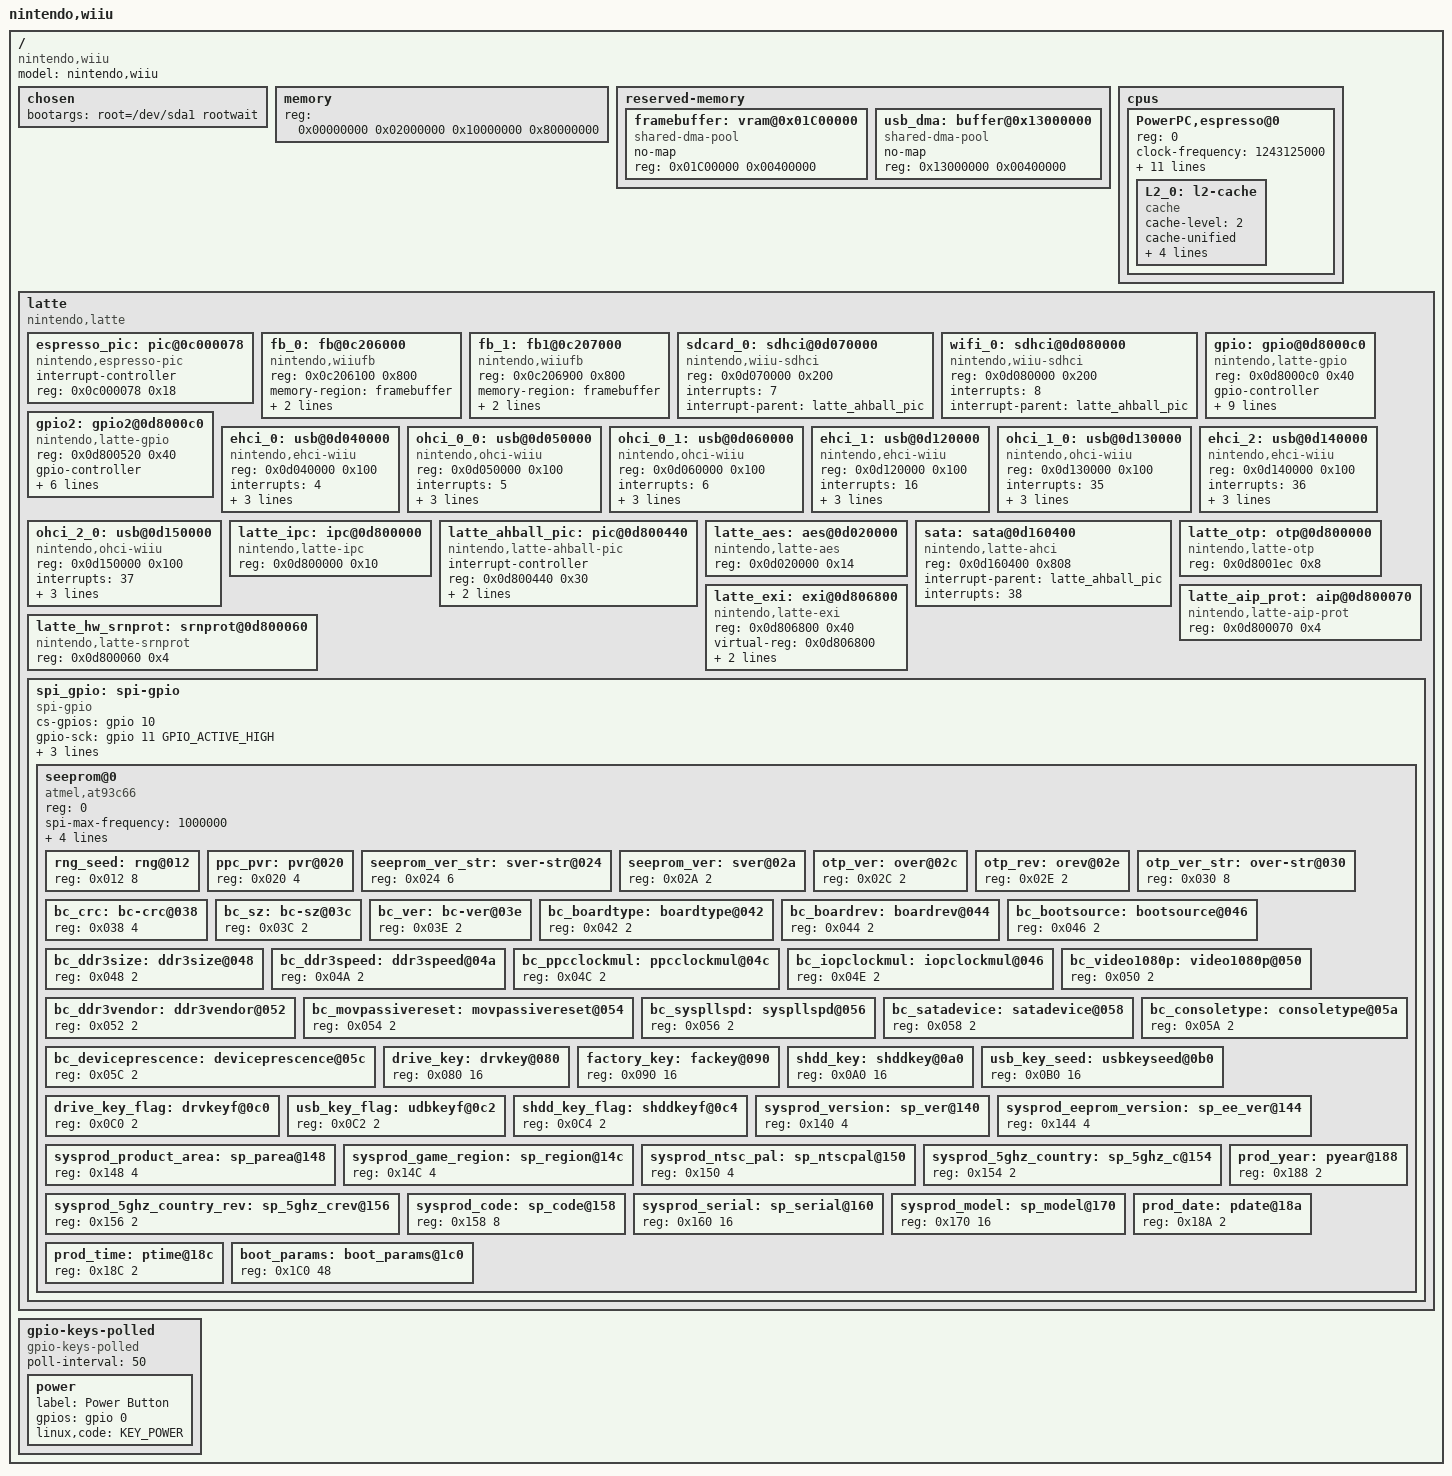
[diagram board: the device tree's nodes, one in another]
/dts-v1/;
#include <dt-bindings/gpio/gpio.h>
#include <dt-bindings/input/input.h>

/ {
    model = "nintendo,wiiu";
    compatible = "nintendo,wiiu";

    #address-cells = <1>;
    #size-cells = <1>;

    chosen {
        bootargs = "root=/dev/sda1 rootwait";
    };

    memory {
        device_type = "memory";
        reg = <0x00000000 0x02000000        /* MEM1 - 32MB */
               0x10000000 0x80000000>;      /* MEM2 - 2GB  */
    };

    reserved-memory {
        #address-cells = <1>;
        #size-cells = <1>;
        ranges;

        framebuffer: vram@0x01C00000 {
            compatible = "shared-dma-pool";
            no-map;

            reg = <0x01C00000 0x00400000>; /* 8 MiB */
        };

        /*Ranges aped from wii-linux-ngx*/
        usb_dma: buffer@0x13000000 {
            compatible = "shared-dma-pool";
            no-map;

            reg = <0x13000000 0x00400000>; /* 8 MiB (512K*7 HCDs+512K spare) */
        };
    };

    cpus {
        #address-cells = <1>;
        #size-cells = <0>;

        PowerPC,espresso@0 {
            device_type = "cpu";
            reg = <0>;
            clock-frequency = <1243125000>;     /* 1.243125GHz */
            bus-frequency = <248625000>;        /* 248.625MHz core-to-bus 5x */
            timebase-frequency = <62156250>;    /* 1/4 of the bus clock */
            i-cache-size = <32768>; /* 32K icache */
            i-cache-line-size = <32>;
            i-cache-block-size = <32>;
            i-cache-sets = <128>;
            d-cache-size = <32768>; /* 32K dcache */
            d-cache-line-size = <32>;
            d-cache-block-size = <32>;
            d-cache-sets = <128>;
            next-level-cache = <&L2_0>;
            L2_0:l2-cache {
                compatible = "cache";
                cache-level = <2>;
                cache-unified;
                cache-size = <0x80000>; /* 512KB L2 */
                cache-line-size = <64>;
                cache-block-size = <32>;
                cache-sets = <2048>;
            };
        };
    };

    latte {
        #address-cells = <1>;
        #size-cells = <1>;
        compatible = "nintendo,latte";
        ranges = <0x0c000000 0x0c000000 0x00400000      /* Espresso registers */
                  0x0d000000 0x0d000000 0x00200000      /* Latte deivces */
                  0x0d800000 0x0d800000 0x00800000>;    /* Latte registers */

        espresso_pic: pic@0c000078 {
            #interrupt-cells = <1>;
            interrupt-controller;

            compatible = "nintendo,espresso-pic";
            reg = <0x0c000078 0x18>;
        };

        fb_0: fb@0c206000 {
            compatible = "nintendo,wiiufb";
            reg = <0x0c206100 0x800>;
            memory-region = <&framebuffer>;

            default-width = <1280>;
            default-height = <720>;
        };

        fb_1: fb1@0c207000 {
            compatible = "nintendo,wiiufb";
            reg = <0x0c206900 0x800>;
            memory-region = <&framebuffer>;

            default-width = <854>;
            default-height = <480>;
        };

        /*gpu7@0c200000 {
            compatible = "nintendo,gpu7";
            #address-cells = <1>;
            #size-cells = <1>;
        };*/ //One day

        sdcard_0: sdhci@0d070000 {
            compatible = "nintendo,wiiu-sdhci";
            reg = <0x0d070000 0x200>;
            interrupts = <7>;
            interrupt-parent = <&latte_ahball_pic>;
        };

        wifi_0: sdhci@0d080000 {
            compatible = "nintendo,wiiu-sdhci";
            reg = <0x0d080000 0x200>;
            interrupts = <8>;
            interrupt-parent = <&latte_ahball_pic>;
        };

        gpio: gpio@0d8000c0 {
            #gpio-cells = <2>;
            compatible = "nintendo,latte-gpio", "nintendo,hollywood-gpio";

            reg = <0x0d8000c0 0x40>;
            gpio-controller;
            /* TODO: we do have a few more gpios */
            ngpios = <24>;

            gpio-line-names =
                "POWER", "DWIFI", "FAN", "DC_DC",
                "", "Esp10WorkAround", "", "",
                "PADPD", "", "EEP_CS", "EEP_CLK",
                "EEP_MOSI", "EEP_MISO", "AVE_SCL", "AVE_SDA",
                "DEBUG0", "DEBUG1", "DEBUG2", "DEBUG3",
                "DEBUG4", "DEBUG5", "DEBUG6", "DEBUG7";

            interrupt-controller;
            #interrupt-cells = <2>;
            interrupts = <10>;
            interrupt-parent = <&latte_ahball_pic>;
        };

        gpio2: gpio2@0d8000c0 {
            #gpio-cells = <2>;
            compatible = "nintendo,latte-gpio", "nintendo,hollywood-gpio";

            reg = <0x0d800520 0x40>;
            gpio-controller;
            ngpios = <7>;

            gpio-line-names =
                "FANSPEED", "SMC_SCL", "SMC_SDA", "DC_DC2",
                "AVE_INT", "", "AVE_RESET";

            interrupt-controller;
            #interrupt-cells = <2>;
            interrupts = <10>;
            interrupt-parent = <&latte_ahball_pic>;
        };

        ehci_0: usb@0d040000 {
            compatible = "nintendo,ehci-wiiu", "usb-ehci";
            reg = <0x0d040000 0x100>;
            interrupts = <4>;
            interrupt-parent = <&latte_ahball_pic>;
            big-endian-regs;
            memory-region = <&usb_dma>;
        };

        ohci_0_0: usb@0d050000 {
            compatible = "nintendo,ohci-wiiu";
            reg = <0x0d050000 0x100>;
            interrupts = <5>;
            interrupt-parent = <&latte_ahball_pic>;

            big-endian-regs;
            memory-region = <&usb_dma>;
        };

        ohci_0_1: usb@0d060000 {
            compatible = "nintendo,ohci-wiiu";
            reg = <0x0d060000 0x100>;
            interrupts = <6>;
            interrupt-parent = <&latte_ahball_pic>;

            big-endian-regs;
            memory-region = <&usb_dma>;
        };

        ehci_1: usb@0d120000 {
            compatible = "nintendo,ehci-wiiu", "usb-ehci";
            reg = <0x0d120000 0x100>;
            interrupts = <16>;
            interrupt-parent = <&latte_ahball_pic>;
            big-endian-regs;
            memory-region = <&usb_dma>;
        };

        ohci_1_0: usb@0d130000 {
            compatible = "nintendo,ohci-wiiu";
            reg = <0x0d130000 0x100>;
            interrupts = <35>;
            interrupt-parent = <&latte_ahball_pic>;

            big-endian-regs;
            memory-region = <&usb_dma>;
        };

        ehci_2: usb@0d140000 {
            compatible = "nintendo,ehci-wiiu", "usb-ehci";
            reg = <0x0d140000 0x100>;
            interrupts = <36>;
            interrupt-parent = <&latte_ahball_pic>;
            big-endian-regs;
            memory-region = <&usb_dma>;
        };

        ohci_2_0: usb@0d150000 {
            compatible = "nintendo,ohci-wiiu";
            reg = <0x0d150000 0x100>;
            interrupts = <37>;
            interrupt-parent = <&latte_ahball_pic>;

            big-endian-regs;
            memory-region = <&usb_dma>;
        };

        latte_ipc: ipc@0d800000 {
            compatible = "nintendo,latte-ipc";
            reg = <0x0d800000 0x10>;
        };

        latte_ahball_pic: pic@0d800440 {
            #interrupt-cells = <1>;
            interrupt-controller;

            compatible = "nintendo,latte-ahball-pic";
            reg = <0x0d800440 0x30>;
            interrupt-parent = <&espresso_pic>;
            interrupts = <24>;
        };

        latte_aes: aes@0d020000 {
            compatible = "nintendo,latte-aes";
            reg = <0x0d020000 0x14>;
        };

        sata: sata@0d160400 {
            compatible = "nintendo,latte-ahci";
            reg = <0x0d160400 0x808>;

            interrupt-parent = <&latte_ahball_pic>;
            interrupts = <38>; //IRQ 7 may be DBGINTs only
        };

        latte_otp: otp@0d800000 {
            compatible = "nintendo,latte-otp";
            reg = <0x0d8001ec 0x8>;
        };

        latte_hw_srnprot: srnprot@0d800060 {
            compatible = "nintendo,latte-srnprot";
            reg = <0x0d800060 0x4>;
        };

        latte_aip_prot: aip@0d800070 {
            compatible = "nintendo,latte-aip-prot";
            reg = <0x0d800070 0x4>;
        };

        latte_exi: exi@0d806800 {
            compatible = "nintendo,latte-exi",
                         "nintendo,hollywood-exi",
                         "nintendo,flipper-exi";
            reg = <0x0d806800 0x40>;
            virtual-reg = <0x0d806800>;
            interrupts = <4>;
            interrupt-parent = <&latte_ahball_pic>;
        };

        spi_gpio: spi-gpio {
            compatible = "spi-gpio";
            #address-cells = <1>;
            #size-cells = <0>;
            status = "okay";

            cs-gpios = <&gpio 10 GPIO_ACTIVE_HIGH>;
            gpio-sck = <&gpio 11 GPIO_ACTIVE_HIGH>;
            gpio-mosi = <&gpio 12 GPIO_ACTIVE_HIGH>;
            gpio-miso = <&gpio 13 GPIO_ACTIVE_HIGH>;
            num-chipselects = <1>;

            seeprom@0 {
                compatible = "atmel,at93c66";
                reg = <0>;
                spi-max-frequency = <1000000>;
                spi-cs-high;
                size = <4096>;
                /* TODO: wiiubrew says this is 16-bit, but I only get the correct values in 8-bit */
                data-size = <8>;
                read-only;

                #address-cells = <1>;
                #size-cells = <1>;

                /* https://wiiubrew.org/wiki/Hardware/SEEPROM */
                rng_seed: rng@012 { reg = <0x012 8>; };
                ppc_pvr: pvr@020 { reg = <0x020 4>; };
                seeprom_ver_str: sver-str@024 { reg = <0x024 6>; };
                seeprom_ver: sver@02a { reg = <0x02A 2>; };
                otp_ver: over@02c { reg = <0x02C 2>; };
                otp_rev: orev@02e { reg = <0x02E 2>; };
                otp_ver_str: over-str@030 { reg = <0x030 8>; };

                bc_crc: bc-crc@038 { reg = <0x038 4>; };
                bc_sz: bc-sz@03c { reg = <0x03C 2>; };
                bc_ver: bc-ver@03e { reg = <0x03E 2>; };
                bc_boardtype: boardtype@042 { reg = <0x042 2>; };
                bc_boardrev: boardrev@044 { reg = <0x044 2>; };
                bc_bootsource: bootsource@046 { reg = <0x046 2>; };
                bc_ddr3size: ddr3size@048 { reg = <0x048 2>; };
                bc_ddr3speed: ddr3speed@04a { reg = <0x04A 2>; };
                bc_ppcclockmul: ppcclockmul@04c { reg = <0x04C 2>; };
                bc_iopclockmul: iopclockmul@046 { reg = <0x04E 2>; };
                bc_video1080p: video1080p@050 { reg = <0x050 2>; };
                bc_ddr3vendor: ddr3vendor@052 { reg = <0x052 2>; };
                bc_movpassivereset: movpassivereset@054 { reg = <0x054 2>; };
                bc_syspllspd: syspllspd@056 { reg = <0x056 2>; };
                bc_satadevice: satadevice@058 { reg = <0x058 2>; };
                bc_consoletype: consoletype@05a { reg = <0x05A 2>; };
                bc_deviceprescence: deviceprescence@05c { reg = <0x05C 2>; };

                drive_key: drvkey@080 { reg = <0x080 16>; };
                factory_key: fackey@090 { reg = <0x090 16>; };
                shdd_key: shddkey@0a0 { reg = <0x0A0 16>; };
                usb_key_seed: usbkeyseed@0b0 { reg = <0x0B0 16>; };
                drive_key_flag: drvkeyf@0c0 { reg = <0x0C0 2>; };
                usb_key_flag: udbkeyf@0c2 { reg = <0x0C2 2>; };
                shdd_key_flag: shddkeyf@0c4 { reg = <0x0C4 2>; };

                sysprod_version: sp_ver@140 { reg = <0x140 4>; };
                sysprod_eeprom_version: sp_ee_ver@144 { reg = <0x144 4>; };
                sysprod_product_area: sp_parea@148 { reg = <0x148 4>; };
                sysprod_game_region: sp_region@14c { reg = <0x14C 4>; };
                sysprod_ntsc_pal: sp_ntscpal@150 { reg = <0x150 4>; };
                sysprod_5ghz_country: sp_5ghz_c@154 { reg = <0x154 2>; };
                sysprod_5ghz_country_rev: sp_5ghz_crev@156 { reg = <0x156 2>; };
                sysprod_code: sp_code@158 { reg = <0x158 8>; };
                sysprod_serial: sp_serial@160 { reg = <0x160 16>; };
                sysprod_model: sp_model@170 { reg = <0x170 16>; };

                prod_year: pyear@188 { reg = <0x188 2>; };
                prod_date: pdate@18a { reg = <0x18A 2>; };
                prod_time: ptime@18c { reg = <0x18C 2>; };

                boot_params: boot_params@1c0 { reg = <0x1C0 48>; };
            };
        };
    };

    /* TODO make this gpio-keyed once hollywood-gpio supports interrupts */
    gpio-keys-polled {
        poll-interval = <50>;
        compatible = "gpio-keys-polled";

        power {
            label = "Power Button";
            gpios = <&gpio 0 GPIO_ACTIVE_HIGH>;
            linux,code = <KEY_POWER>;
        };
    };
};
